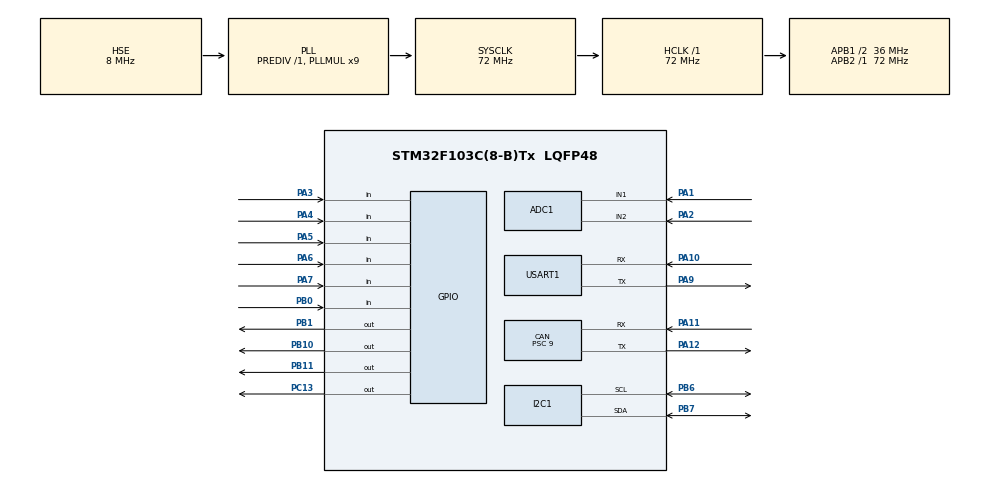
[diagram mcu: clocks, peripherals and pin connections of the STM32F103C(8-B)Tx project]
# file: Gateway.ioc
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ADC1.Channel-1\#ChannelRegularConversion=ADC_CHANNEL_1
ADC1.Channel-2\#ChannelRegularConversion=ADC_CHANNEL_2
ADC1.Channel-4\#ChannelRegularConversion=ADC_CHANNEL_VREFINT
ADC1.ContinuousConvMode=ENABLE
ADC1.NbrOfConversion=3
ADC1.NbrOfConversionFlag=1
ADC1.Rank-1\#ChannelRegularConversion=1
ADC1.Rank-2\#ChannelRegularConversion=2
ADC1.Rank-4\#ChannelRegularConversion=3
ADC1.SamplingTime-1\#ChannelRegularConversion=ADC_SAMPLETIME_7CYCLES_5
ADC1.SamplingTime-2\#ChannelRegularConversion=ADC_SAMPLETIME_7CYCLES_5
ADC1.SamplingTime-4\#ChannelRegularConversion=ADC_SAMPLETIME_55CYCLES_5
ADC1.master=1
CAN.BS1=CAN_BS1_4TQ
CAN.BS2=CAN_BS2_3TQ
CAN.CalculateBaudRate=500000
CAN.CalculateTimeBit=2000
CAN.CalculateTimeQuantum=250.0
CAN.NART=ENABLE
CAN.Prescaler=9
CAN.TXFP=ENABLE
Dma.ADC1.2.Direction=DMA_PERIPH_TO_MEMORY
Dma.ADC1.2.Instance=DMA1_Channel1
Dma.ADC1.2.MemDataAlignment=DMA_MDATAALIGN_HALFWORD
Dma.ADC1.2.MemInc=DMA_MINC_ENABLE
Dma.ADC1.2.Mode=DMA_CIRCULAR
Dma.ADC1.2.PeriphDataAlignment=DMA_PDATAALIGN_HALFWORD
Dma.ADC1.2.PeriphInc=DMA_PINC_DISABLE
Dma.ADC1.2.Priority=DMA_PRIORITY_LOW
Dma.Request0=USART1_RX
Dma.Request1=USART1_TX
Dma.Request2=ADC1
Dma.USART1_RX.0.Direction=DMA_PERIPH_TO_MEMORY
Dma.USART1_RX.0.Instance=DMA1_Channel5
Dma.USART1_RX.0.MemDataAlignment=DMA_MDATAALIGN_BYTE
Dma.USART1_RX.0.MemInc=DMA_MINC_ENABLE
Dma.USART1_RX.0.Mode=DMA_NORMAL
Dma.USART1_RX.0.PeriphDataAlignment=DMA_PDATAALIGN_BYTE
Dma.USART1_RX.0.PeriphInc=DMA_PINC_DISABLE
Dma.USART1_RX.0.Priority=DMA_PRIORITY_LOW
Dma.USART1_TX.1.Direction=DMA_MEMORY_TO_PERIPH
Dma.USART1_TX.1.Instance=DMA1_Channel4
Dma.USART1_TX.1.MemDataAlignment=DMA_MDATAALIGN_BYTE
Dma.USART1_TX.1.MemInc=DMA_MINC_ENABLE
Dma.USART1_TX.1.Mode=DMA_NORMAL
Dma.USART1_TX.1.PeriphDataAlignment=DMA_PDATAALIGN_BYTE
Dma.USART1_TX.1.PeriphInc=DMA_PINC_DISABLE
Dma.USART1_TX.1.Priority=DMA_PRIORITY_LOW
FREERTOS.BinarySemaphores01=TX_BS,Static,TX_BSControlBlock,Available
FREERTOS.HEAP_NUMBER=4
FREERTOS.Queues01=RX_Q,8,uint8_t,0,Static,RX_QBuffer,RX_QControlBlock;KEY_Q,8,Debounce_Event_packet_t,0,Static,KEY_QBuffer,KEY_QControlBlock;CAN_F0_Q,8,BSP_CAN_Packet_t,0,Static,CAN_F0_QBuffer,CAN_F0_QControlBlock;CAN_F1_Q,8,BSP_CAN_Packet_t,0,Static,CAN_F1_QBuffer,CAN_F1_QControlBlock
FREERTOS.Tasks01=OLED_T,38,128,Task_OLED,As weak,NULL,Static,OLED_TBuffer,OLED_TControlBlock;RX_T,51,200,Task_RX,As weak,NULL,Static,RX_TBuffer,RX_TControlBlock;TX_T,38,128,Task_TX,As weak,NULL,Static,TX_TBuffer,TX_TControlBlock;KEY_T,52,80,Task_KEY,As weak,NULL,Static,KEY_TBuffer,KEY_TControlBlock;PAR_T,46,80,Task_PAR,As weak,NULL,Static,PAR_TBuffer,PAR_TControlBlock;CAN_F0_T,54,128,Task_CAN_F0,As weak,NULL,Static,CAN_F0_TBuffer,CAN_F0_TControlBlock;CAN_F1_T,53,128,Task_CAN_F1,As weak,NULL,Static,CAN_F1_TBuffer,CAN_F1_TControlBlock
FREERTOS.configMINIMAL_STACK_SIZE=64
FREERTOS.configTOTAL_HEAP_SIZE=256
I2C1.I2C_Mode=I2C_Fast
Mcu.Family=STM32F1
Mcu.Name=STM32F103C(8-B)Tx
Mcu.Package=LQFP48
NVIC.CAN1_RX1_IRQn=true\:5\:0\:false\:false\:true\:true\:true\:true\:true
NVIC.DMA1_Channel1_IRQn=true\:5\:0\:false\:false\:true\:true\:false\:true\:true
NVIC.DMA1_Channel4_IRQn=true\:5\:0\:false\:false\:true\:true\:false\:true\:true
NVIC.DMA1_Channel5_IRQn=true\:5\:0\:false\:false\:true\:true\:false\:true\:true
NVIC.PriorityGroup=NVIC_PRIORITYGROUP_4
NVIC.TIM4_IRQn=true\:15\:0\:false\:false\:true\:false\:false\:true\:true
NVIC.TimeBase=TIM4_IRQn
NVIC.TimeBaseIP=TIM4
NVIC.USART1_IRQn=true\:5\:0\:false\:false\:true\:true\:true\:true\:true
NVIC.USB_LP_CAN1_RX0_IRQn=true\:5\:0\:false\:false\:true\:true\:true\:true\:true
PA1.Signal=ADCx_IN1
PA10.Mode=Asynchronous
PA10.Signal=USART1_RX
PA11.Mode=CAN_Activate
PA11.Signal=CAN_RX
PA12.Mode=CAN_Activate
PA12.Signal=CAN_TX
PA13.Mode=Serial_Wire
PA13.Signal=SYS_JTMS-SWDIO
PA14.Mode=Serial_Wire
PA14.Signal=SYS_JTCK-SWCLK
PA2.Signal=ADCx_IN2
PA3.GPIO_Mode=GPIO_MODE_INPUT
PA3.GPIO_PuPd=GPIO_PULLDOWN
PA3.Signal=GPIO_Input
PA4.GPIO_Mode=GPIO_MODE_INPUT
PA4.GPIO_PuPd=GPIO_PULLDOWN
PA4.Signal=GPIO_Input
PA5.GPIO_Mode=GPIO_MODE_INPUT
PA5.GPIO_PuPd=GPIO_PULLDOWN
PA5.Signal=GPIO_Input
PA6.GPIO_Mode=GPIO_MODE_INPUT
PA6.GPIO_PuPd=GPIO_PULLDOWN
PA6.Signal=GPIO_Input
PA7.GPIO_Mode=GPIO_MODE_INPUT
PA7.GPIO_PuPd=GPIO_PULLDOWN
PA7.Signal=GPIO_Input
PA9.Mode=Asynchronous
PA9.Signal=USART1_TX
PB0.GPIO_Mode=GPIO_MODE_INPUT
PB0.GPIO_PuPd=GPIO_PULLDOWN
PB0.Signal=GPIO_Input
PB1.GPIO_ModeDefaultOutputPP=GPIO_MODE_OUTPUT_PP
PB1.GPIO_PuPd=GPIO_PULLUP
PB1.GPIO_Speed=GPIO_SPEED_FREQ_LOW
PB1.PinState=GPIO_PIN_SET
PB1.Signal=GPIO_Output
PB10.GPIO_ModeDefaultOutputPP=GPIO_MODE_OUTPUT_PP
PB10.GPIO_PuPd=GPIO_PULLUP
PB10.GPIO_Speed=GPIO_SPEED_FREQ_LOW
PB10.PinState=GPIO_PIN_SET
PB10.Signal=GPIO_Output
PB11.GPIO_ModeDefaultOutputPP=GPIO_MODE_OUTPUT_PP
PB11.GPIO_PuPd=GPIO_PULLUP
PB11.GPIO_Speed=GPIO_SPEED_FREQ_LOW
PB11.PinState=GPIO_PIN_SET
PB11.Signal=GPIO_Output
PB6.Mode=I2C
PB6.Signal=I2C1_SCL
PB7.Mode=I2C
PB7.Signal=I2C1_SDA
PC13-TAMPER-RTC.GPIO_ModeDefaultOutputPP=GPIO_MODE_OUTPUT_OD
PC13-TAMPER-RTC.GPIO_PuPd=GPIO_PULLUP
PC13-TAMPER-RTC.PinState=GPIO_PIN_SET
PC13-TAMPER-RTC.Signal=GPIO_Output
PD0-OSC_IN.Mode=HSE-External-Oscillator
PD0-OSC_IN.Signal=RCC_OSC_IN
PD1-OSC_OUT.Mode=HSE-External-Oscillator
PD1-OSC_OUT.Signal=RCC_OSC_OUT
ProjectManager.HeapSize=0x200
ProjectManager.StackSize=0x400
ProjectManager.TargetToolchain=CMake
RCC.ADCPresc=RCC_ADCPCLK2_DIV6
RCC.AHBFreq_Value=72000000
RCC.APB1CLKDivider=RCC_HCLK_DIV2
RCC.APB1Freq_Value=36000000
RCC.APB1TimFreq_Value=72000000
RCC.APB2Freq_Value=72000000
RCC.APB2TimFreq_Value=72000000
RCC.HCLKFreq_Value=72000000
RCC.PLLMUL=RCC_PLL_MUL9
RCC.PLLSourceVirtual=RCC_PLLSOURCE_HSE
RCC.SYSCLKFreq_VALUE=72000000
RCC.SYSCLKSource=RCC_SYSCLKSOURCE_PLLCLK
RCC.USBFreq_Value=72000000
SH.ADCx_IN1.0=ADC1_IN1,IN1
SH.ADCx_IN2.0=ADC1_IN2,IN2
USART1.VirtualMode=VM_ASYNC
VP_ADC1_Vref_Input.Mode=IN-Vrefint
VP_FREERTOS_VS_CMSIS_V2.Mode=CMSIS_V2
VP_SYS_VS_tim4.Mode=TIM4
board=custom

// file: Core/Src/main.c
/* USER CODE BEGIN Header */
/**
  ******************************************************************************
  * @file           : main.c
  * @brief          : Main program body
  ******************************************************************************
  * @attention
  *
  * Copyright (c) 2026 STMicroelectronics.
  * All rights reserved.
  *
  * This software is licensed under terms that can be found in the LICENSE file
  * in the root directory of this software component.
  * If no LICENSE file comes with this software, it is provided AS-IS.
  *
  ******************************************************************************
  */
/* USER CODE END Header */
#include "main.h"
#include "cmsis_os.h"
#include "adc.h"
#include "can.h"
#include "dma.h"
#include "i2c.h"
#include "usart.h"
#include "gpio.h"

void SystemClock_Config(void);
void MX_FREERTOS_Init(void);

int main(void)
{

  /* MCU Configuration--------------------------------------------------------*/

  /* Reset of all peripherals, Initializes the Flash interface and the Systick. */
  HAL_Init();

  /* Configure the system clock */
  SystemClock_Config();

  /* Initialize all configured peripherals */
  MX_GPIO_Init();
  MX_DMA_Init();
  MX_CAN_Init();
  MX_I2C1_Init();
  MX_USART1_UART_Init();
  MX_ADC1_Init();

  /* Init scheduler */
  osKernelInitialize();  /* Call init function for freertos objects (in cmsis_os2.c) */
  MX_FREERTOS_Init();

  /* Start scheduler */
  osKernelStart();

  /* We should never get here as control is now taken by the scheduler */

  /* Infinite loop */
  while (1)
  {

  }
}

void SystemClock_Config(void)
{
  RCC_OscInitTypeDef RCC_OscInitStruct = {0};
  RCC_ClkInitTypeDef RCC_ClkInitStruct = {0};
  RCC_PeriphCLKInitTypeDef PeriphClkInit = {0};

  /** Initializes the RCC Oscillators according to the specified parameters
  * in the RCC_OscInitTypeDef structure.
  */
  RCC_OscInitStruct.OscillatorType = RCC_OSCILLATORTYPE_HSE;
  RCC_OscInitStruct.HSEState = RCC_HSE_ON;
  RCC_OscInitStruct.HSEPredivValue = RCC_HSE_PREDIV_DIV1;
  RCC_OscInitStruct.HSIState = RCC_HSI_ON;
  RCC_OscInitStruct.PLL.PLLState = RCC_PLL_ON;
  RCC_OscInitStruct.PLL.PLLSource = RCC_PLLSOURCE_HSE;
  RCC_OscInitStruct.PLL.PLLMUL = RCC_PLL_MUL9;
  if (HAL_RCC_OscConfig(&RCC_OscInitStruct) != HAL_OK)
  {
    Error_Handler();
  }

  /** Initializes the CPU, AHB and APB buses clocks
  */
  RCC_ClkInitStruct.ClockType = RCC_CLOCKTYPE_HCLK|RCC_CLOCKTYPE_SYSCLK
                              |RCC_CLOCKTYPE_PCLK1|RCC_CLOCKTYPE_PCLK2;
  RCC_ClkInitStruct.SYSCLKSource = RCC_SYSCLKSOURCE_PLLCLK;
  RCC_ClkInitStruct.AHBCLKDivider = RCC_SYSCLK_DIV1;
  RCC_ClkInitStruct.APB1CLKDivider = RCC_HCLK_DIV2;
  RCC_ClkInitStruct.APB2CLKDivider = RCC_HCLK_DIV1;

  if (HAL_RCC_ClockConfig(&RCC_ClkInitStruct, FLASH_LATENCY_2) != HAL_OK)
  {
    Error_Handler();
  }
  PeriphClkInit.PeriphClockSelection = RCC_PERIPHCLK_ADC;
  PeriphClkInit.AdcClockSelection = RCC_ADCPCLK2_DIV6;
  if (HAL_RCCEx_PeriphCLKConfig(&PeriphClkInit) != HAL_OK)
  {
    Error_Handler();
  }
}

void HAL_TIM_PeriodElapsedCallback(TIM_HandleTypeDef *htim)
{
  if (htim->Instance == TIM4)
  {
    HAL_IncTick();
  }
}

void Error_Handler(void)
{
  __disable_irq();
  while (1)
  {
  }
}

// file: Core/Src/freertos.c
/* USER CODE BEGIN Header */
/**
  ******************************************************************************
  * File Name          : freertos.c
  * Description        : Code for freertos applications
  ******************************************************************************
  * @attention
  *
  * Copyright (c) 2026 STMicroelectronics.
  * All rights reserved.
  *
  * This software is licensed under terms that can be found in the LICENSE file
  * in the root directory of this software component.
  * If no LICENSE file comes with this software, it is provided AS-IS.
  *
  ******************************************************************************
  */
/* USER CODE END Header */

#include "FreeRTOS.h"
#include "task.h"
#include "main.h"
#include "cmsis_os.h"

/* USER CODE BEGIN Includes */
#include "debounce.h"
#include "bsp_can.h"
/* USER CODE END Includes */

typedef StaticTask_t osStaticThreadDef_t;
typedef StaticQueue_t osStaticMessageQDef_t;
typedef StaticSemaphore_t osStaticSemaphoreDef_t;

/* Definitions for OLED_T */
osThreadId_t OLED_THandle;
uint32_t OLED_TBuffer[ 128 ];
osStaticThreadDef_t OLED_TControlBlock;
const osThreadAttr_t OLED_T_attributes = {
  .name = "OLED_T",
  .cb_mem = &OLED_TControlBlock,
  .cb_size = sizeof(OLED_TControlBlock),
  .stack_mem = &OLED_TBuffer[0],
  .stack_size = sizeof(OLED_TBuffer),
  .priority = (osPriority_t) osPriorityAboveNormal6,
};
/* Definitions for RX_T */
osThreadId_t RX_THandle;
uint32_t RX_TBuffer[ 200 ];
osStaticThreadDef_t RX_TControlBlock;
const osThreadAttr_t RX_T_attributes = {
  .name = "RX_T",
  .cb_mem = &RX_TControlBlock,
  .cb_size = sizeof(RX_TControlBlock),
  .stack_mem = &RX_TBuffer[0],
  .stack_size = sizeof(RX_TBuffer),
  .priority = (osPriority_t) osPriorityRealtime3,
};
/* Definitions for TX_T */
osThreadId_t TX_THandle;
uint32_t TX_TBuffer[ 128 ];
osStaticThreadDef_t TX_TControlBlock;
const osThreadAttr_t TX_T_attributes = {
  .name = "TX_T",
  .cb_mem = &TX_TControlBlock,
  .cb_size = sizeof(TX_TControlBlock),
  .stack_mem = &TX_TBuffer[0],
  .stack_size = sizeof(TX_TBuffer),
  .priority = (osPriority_t) osPriorityAboveNormal6,
};
/* Definitions for KEY_T */
osThreadId_t KEY_THandle;
uint32_t KEY_TBuffer[ 80 ];
osStaticThreadDef_t KEY_TControlBlock;
const osThreadAttr_t KEY_T_attributes = {
  .name = "KEY_T",
  .cb_mem = &KEY_TControlBlock,
  .cb_size = sizeof(KEY_TControlBlock),
  .stack_mem = &KEY_TBuffer[0],
  .stack_size = sizeof(KEY_TBuffer),
  .priority = (osPriority_t) osPriorityRealtime4,
};
/* Definitions for PAR_T */
osThreadId_t PAR_THandle;
uint32_t PAR_TBuffer[ 80 ];
osStaticThreadDef_t PAR_TControlBlock;
const osThreadAttr_t PAR_T_attributes = {
  .name = "PAR_T",
  .cb_mem = &PAR_TControlBlock,
  .cb_size = sizeof(PAR_TControlBlock),
  .stack_mem = &PAR_TBuffer[0],
  .stack_size = sizeof(PAR_TBuffer),
  .priority = (osPriority_t) osPriorityHigh6,
};
/* Definitions for CAN_F0_T */
osThreadId_t CAN_F0_THandle;
uint32_t CAN_F0_TBuffer[ 128 ];
osStaticThreadDef_t CAN_F0_TControlBlock;
const osThreadAttr_t CAN_F0_T_attributes = {
  .name = "CAN_F0_T",
  .cb_mem = &CAN_F0_TControlBlock,
  .cb_size = sizeof(CAN_F0_TControlBlock),
  .stack_mem = &CAN_F0_TBuffer[0],
  .stack_size = sizeof(CAN_F0_TBuffer),
  .priority = (osPriority_t) osPriorityRealtime6,
};
/* Definitions for CAN_F1_T */
osThreadId_t CAN_F1_THandle;
uint32_t CAN_F1_TBuffer[ 128 ];
osStaticThreadDef_t CAN_F1_TControlBlock;
const osThreadAttr_t CAN_F1_T_attributes = {
  .name = "CAN_F1_T",
  .cb_mem = &CAN_F1_TControlBlock,
  .cb_size = sizeof(CAN_F1_TControlBlock),
  .stack_mem = &CAN_F1_TBuffer[0],
  .stack_size = sizeof(CAN_F1_TBuffer),
  .priority = (osPriority_t) osPriorityRealtime5,
};
/* Definitions for RX_Q */
osMessageQueueId_t RX_QHandle;
uint8_t RX_QBuffer[ 8 * sizeof( uint8_t ) ];
osStaticMessageQDef_t RX_QControlBlock;
const osMessageQueueAttr_t RX_Q_attributes = {
  .name = "RX_Q",
  .cb_mem = &RX_QControlBlock,
  .cb_size = sizeof(RX_QControlBlock),
  .mq_mem = &RX_QBuffer,
  .mq_size = sizeof(RX_QBuffer)
};
/* Definitions for KEY_Q */
osMessageQueueId_t KEY_QHandle;
uint8_t KEY_QBuffer[ 8 * sizeof( Debounce_Event_packet_t ) ];
osStaticMessageQDef_t KEY_QControlBlock;
const osMessageQueueAttr_t KEY_Q_attributes = {
  .name = "KEY_Q",
  .cb_mem = &KEY_QControlBlock,
  .cb_size = sizeof(KEY_QControlBlock),
  .mq_mem = &KEY_QBuffer,
  .mq_size = sizeof(KEY_QBuffer)
};
/* Definitions for CAN_F0_Q */
osMessageQueueId_t CAN_F0_QHandle;
uint8_t CAN_F0_QBuffer[ 8 * sizeof( BSP_CAN_Packet_t ) ];
osStaticMessageQDef_t CAN_F0_QControlBlock;
const osMessageQueueAttr_t CAN_F0_Q_attributes = {
  .name = "CAN_F0_Q",
  .cb_mem = &CAN_F0_QControlBlock,
  .cb_size = sizeof(CAN_F0_QControlBlock),
  .mq_mem = &CAN_F0_QBuffer,
  .mq_size = sizeof(CAN_F0_QBuffer)
};
/* Definitions for CAN_F1_Q */
osMessageQueueId_t CAN_F1_QHandle;
uint8_t CAN_F1_QBuffer[ 8 * sizeof( BSP_CAN_Packet_t ) ];
osStaticMessageQDef_t CAN_F1_QControlBlock;
const osMessageQueueAttr_t CAN_F1_Q_attributes = {
  .name = "CAN_F1_Q",
  .cb_mem = &CAN_F1_QControlBlock,
  .cb_size = sizeof(CAN_F1_QControlBlock),
  .mq_mem = &CAN_F1_QBuffer,
  .mq_size = sizeof(CAN_F1_QBuffer)
};
/* Definitions for TX_BS */
osSemaphoreId_t TX_BSHandle;
osStaticSemaphoreDef_t TX_BSControlBlock;
const osSemaphoreAttr_t TX_BS_attributes = {
  .name = "TX_BS",
  .cb_mem = &TX_BSControlBlock,
  .cb_size = sizeof(TX_BSControlBlock),
};

void Task_OLED(void *argument);
void Task_RX(void *argument);
void Task_TX(void *argument);
void Task_KEY(void *argument);
void Task_PAR(void *argument);
void Task_CAN_F0(void *argument);
void Task_CAN_F1(void *argument);

void MX_FREERTOS_Init(void); /* (MISRA C 2004 rule 8.1) */

void MX_FREERTOS_Init(void) {

  /* Create the semaphores(s) */
  /* creation of TX_BS */
  TX_BSHandle = osSemaphoreNew(1, 1, &TX_BS_attributes);

  /* Create the queue(s) */
  /* creation of RX_Q */
  RX_QHandle = osMessageQueueNew (8, sizeof(uint8_t), &RX_Q_attributes);

  /* creation of KEY_Q */
  KEY_QHandle = osMessageQueueNew (8, sizeof(Debounce_Event_packet_t), &KEY_Q_attributes);

  /* creation of CAN_F0_Q */
  CAN_F0_QHandle = osMessageQueueNew (8, sizeof(BSP_CAN_Packet_t), &CAN_F0_Q_attributes);

  /* creation of CAN_F1_Q */
  CAN_F1_QHandle = osMessageQueueNew (8, sizeof(BSP_CAN_Packet_t), &CAN_F1_Q_attributes);

  /* Create the thread(s) */
  /* creation of OLED_T */
  OLED_THandle = osThreadNew(Task_OLED, NULL, &OLED_T_attributes);

  /* creation of RX_T */
  RX_THandle = osThreadNew(Task_RX, NULL, &RX_T_attributes);

  /* creation of TX_T */
  TX_THandle = osThreadNew(Task_TX, NULL, &TX_T_attributes);

  /* creation of KEY_T */
  KEY_THandle = osThreadNew(Task_KEY, NULL, &KEY_T_attributes);

  /* creation of PAR_T */
  PAR_THandle = osThreadNew(Task_PAR, NULL, &PAR_T_attributes);

  /* creation of CAN_F0_T */
  CAN_F0_THandle = osThreadNew(Task_CAN_F0, NULL, &CAN_F0_T_attributes);

  /* creation of CAN_F1_T */
  CAN_F1_THandle = osThreadNew(Task_CAN_F1, NULL, &CAN_F1_T_attributes);

}

__weak void Task_OLED(void *argument)
{
  for(;;)
  {
    osDelay(1);
  }
}

__weak void Task_RX(void *argument)
{
  for(;;)
  {
    osDelay(1);
  }
}

__weak void Task_TX(void *argument)
{
  for(;;)
  {
    osDelay(1);
  }
}

__weak void Task_KEY(void *argument)
{
  for(;;)
  {
    osDelay(1);
  }
}

__weak void Task_PAR(void *argument)
{
  for(;;)
  {
    osDelay(1);
  }
}

__weak void Task_CAN_F0(void *argument)
{
  for(;;)
  {
    osDelay(1);
  }
}

__weak void Task_CAN_F1(void *argument)
{
  for(;;)
  {
    osDelay(1);
  }
}
